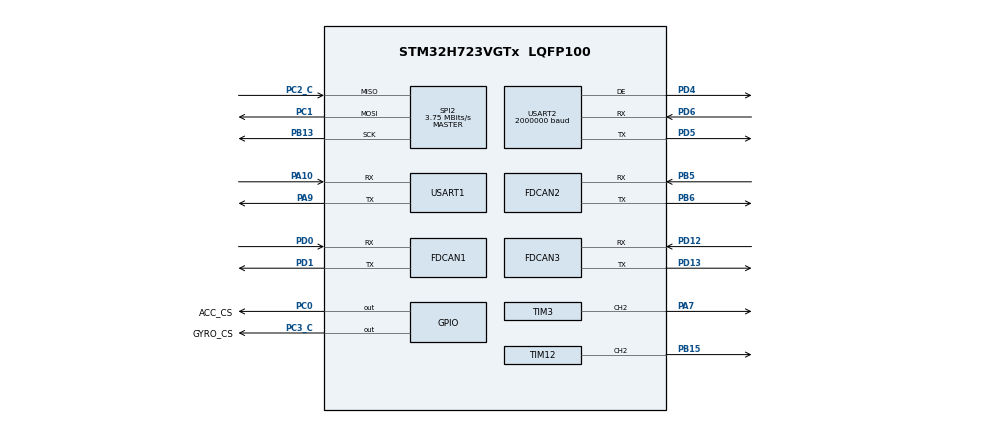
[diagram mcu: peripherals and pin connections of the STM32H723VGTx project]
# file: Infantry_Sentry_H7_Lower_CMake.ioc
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CORTEX_M7.default_mode_Activation=1
Dma.Request0=SPI2_RX
Dma.Request1=SPI2_TX
Dma.Request2=TIM3_CH2
Dma.Request3=USART1_RX
Dma.Request4=USART1_TX
Dma.Request5=USART2_RX
Dma.Request6=USART2_TX
Dma.SPI2_RX.0.Direction=DMA_PERIPH_TO_MEMORY
Dma.SPI2_RX.0.EventEnable=DISABLE
Dma.SPI2_RX.0.FIFOMode=DMA_FIFOMODE_DISABLE
Dma.SPI2_RX.0.Instance=DMA1_Stream0
Dma.SPI2_RX.0.MemDataAlignment=DMA_MDATAALIGN_BYTE
Dma.SPI2_RX.0.MemInc=DMA_MINC_ENABLE
Dma.SPI2_RX.0.Mode=DMA_NORMAL
Dma.SPI2_RX.0.PeriphDataAlignment=DMA_PDATAALIGN_BYTE
Dma.SPI2_RX.0.PeriphInc=DMA_PINC_DISABLE
Dma.SPI2_RX.0.Polarity=HAL_DMAMUX_REQ_GEN_RISING
Dma.SPI2_RX.0.Priority=DMA_PRIORITY_VERY_HIGH
Dma.SPI2_RX.0.RequestNumber=1
Dma.SPI2_RX.0.SignalID=NONE
Dma.SPI2_RX.0.SyncEnable=DISABLE
Dma.SPI2_RX.0.SyncPolarity=HAL_DMAMUX_SYNC_NO_EVENT
Dma.SPI2_RX.0.SyncRequestNumber=1
Dma.SPI2_RX.0.SyncSignalID=NONE
Dma.SPI2_TX.1.Direction=DMA_MEMORY_TO_PERIPH
Dma.SPI2_TX.1.EventEnable=DISABLE
Dma.SPI2_TX.1.FIFOMode=DMA_FIFOMODE_DISABLE
Dma.SPI2_TX.1.Instance=DMA1_Stream1
Dma.SPI2_TX.1.MemDataAlignment=DMA_MDATAALIGN_BYTE
Dma.SPI2_TX.1.MemInc=DMA_MINC_ENABLE
Dma.SPI2_TX.1.Mode=DMA_NORMAL
Dma.SPI2_TX.1.PeriphDataAlignment=DMA_PDATAALIGN_BYTE
Dma.SPI2_TX.1.PeriphInc=DMA_PINC_DISABLE
Dma.SPI2_TX.1.Polarity=HAL_DMAMUX_REQ_GEN_RISING
Dma.SPI2_TX.1.Priority=DMA_PRIORITY_VERY_HIGH
Dma.SPI2_TX.1.RequestNumber=1
Dma.SPI2_TX.1.SignalID=NONE
Dma.SPI2_TX.1.SyncEnable=DISABLE
Dma.SPI2_TX.1.SyncPolarity=HAL_DMAMUX_SYNC_NO_EVENT
Dma.SPI2_TX.1.SyncRequestNumber=1
Dma.SPI2_TX.1.SyncSignalID=NONE
Dma.TIM3_CH2.2.Direction=DMA_MEMORY_TO_PERIPH
Dma.TIM3_CH2.2.EventEnable=DISABLE
Dma.TIM3_CH2.2.FIFOMode=DMA_FIFOMODE_DISABLE
Dma.TIM3_CH2.2.Instance=DMA1_Stream2
Dma.TIM3_CH2.2.MemDataAlignment=DMA_MDATAALIGN_HALFWORD
Dma.TIM3_CH2.2.MemInc=DMA_MINC_ENABLE
Dma.TIM3_CH2.2.Mode=DMA_NORMAL
Dma.TIM3_CH2.2.PeriphDataAlignment=DMA_PDATAALIGN_HALFWORD
Dma.TIM3_CH2.2.PeriphInc=DMA_PINC_DISABLE
Dma.TIM3_CH2.2.Polarity=HAL_DMAMUX_REQ_GEN_RISING
Dma.TIM3_CH2.2.Priority=DMA_PRIORITY_LOW
Dma.TIM3_CH2.2.RequestNumber=1
Dma.TIM3_CH2.2.SignalID=NONE
Dma.TIM3_CH2.2.SyncEnable=DISABLE
Dma.TIM3_CH2.2.SyncPolarity=HAL_DMAMUX_SYNC_NO_EVENT
Dma.TIM3_CH2.2.SyncRequestNumber=1
Dma.TIM3_CH2.2.SyncSignalID=NONE
Dma.USART1_RX.3.Direction=DMA_PERIPH_TO_MEMORY
Dma.USART1_RX.3.EventEnable=DISABLE
Dma.USART1_RX.3.FIFOMode=DMA_FIFOMODE_DISABLE
Dma.USART1_RX.3.Instance=DMA2_Stream0
Dma.USART1_RX.3.MemDataAlignment=DMA_MDATAALIGN_BYTE
Dma.USART1_RX.3.MemInc=DMA_MINC_ENABLE
Dma.USART1_RX.3.Mode=DMA_NORMAL
Dma.USART1_RX.3.PeriphDataAlignment=DMA_PDATAALIGN_BYTE
Dma.USART1_RX.3.PeriphInc=DMA_PINC_DISABLE
Dma.USART1_RX.3.Polarity=HAL_DMAMUX_REQ_GEN_RISING
Dma.USART1_RX.3.Priority=DMA_PRIORITY_LOW
Dma.USART1_RX.3.RequestNumber=1
Dma.USART1_RX.3.SignalID=NONE
Dma.USART1_RX.3.SyncEnable=DISABLE
Dma.USART1_RX.3.SyncPolarity=HAL_DMAMUX_SYNC_NO_EVENT
Dma.USART1_RX.3.SyncRequestNumber=1
Dma.USART1_RX.3.SyncSignalID=NONE
Dma.USART1_TX.4.Direction=DMA_MEMORY_TO_PERIPH
Dma.USART1_TX.4.EventEnable=DISABLE
Dma.USART1_TX.4.FIFOMode=DMA_FIFOMODE_DISABLE
Dma.USART1_TX.4.Instance=DMA2_Stream1
Dma.USART1_TX.4.MemDataAlignment=DMA_MDATAALIGN_BYTE
Dma.USART1_TX.4.MemInc=DMA_MINC_ENABLE
Dma.USART1_TX.4.Mode=DMA_NORMAL
Dma.USART1_TX.4.PeriphDataAlignment=DMA_PDATAALIGN_BYTE
Dma.USART1_TX.4.PeriphInc=DMA_PINC_DISABLE
Dma.USART1_TX.4.Polarity=HAL_DMAMUX_REQ_GEN_RISING
Dma.USART1_TX.4.Priority=DMA_PRIORITY_LOW
Dma.USART1_TX.4.RequestNumber=1
Dma.USART1_TX.4.SignalID=NONE
Dma.USART1_TX.4.SyncEnable=DISABLE
Dma.USART1_TX.4.SyncPolarity=HAL_DMAMUX_SYNC_NO_EVENT
Dma.USART1_TX.4.SyncRequestNumber=1
Dma.USART1_TX.4.SyncSignalID=NONE
Dma.USART2_RX.5.Direction=DMA_PERIPH_TO_MEMORY
Dma.USART2_RX.5.EventEnable=DISABLE
Dma.USART2_RX.5.FIFOMode=DMA_FIFOMODE_DISABLE
Dma.USART2_RX.5.Instance=DMA1_Stream4
Dma.USART2_RX.5.MemDataAlignment=DMA_MDATAALIGN_BYTE
Dma.USART2_RX.5.MemInc=DMA_MINC_ENABLE
Dma.USART2_RX.5.Mode=DMA_NORMAL
Dma.USART2_RX.5.PeriphDataAlignment=DMA_PDATAALIGN_BYTE
Dma.USART2_RX.5.PeriphInc=DMA_PINC_DISABLE
Dma.USART2_RX.5.Polarity=HAL_DMAMUX_REQ_GEN_RISING
Dma.USART2_RX.5.Priority=DMA_PRIORITY_MEDIUM
Dma.USART2_RX.5.RequestNumber=1
Dma.USART2_RX.5.SignalID=NONE
Dma.USART2_RX.5.SyncEnable=DISABLE
Dma.USART2_RX.5.SyncPolarity=HAL_DMAMUX_SYNC_NO_EVENT
Dma.USART2_RX.5.SyncRequestNumber=1
Dma.USART2_RX.5.SyncSignalID=NONE
Dma.USART2_TX.6.Direction=DMA_MEMORY_TO_PERIPH
Dma.USART2_TX.6.EventEnable=DISABLE
Dma.USART2_TX.6.FIFOMode=DMA_FIFOMODE_DISABLE
Dma.USART2_TX.6.Instance=DMA1_Stream5
Dma.USART2_TX.6.MemDataAlignment=DMA_MDATAALIGN_BYTE
Dma.USART2_TX.6.MemInc=DMA_MINC_ENABLE
Dma.USART2_TX.6.Mode=DMA_NORMAL
Dma.USART2_TX.6.PeriphDataAlignment=DMA_PDATAALIGN_BYTE
Dma.USART2_TX.6.PeriphInc=DMA_PINC_DISABLE
Dma.USART2_TX.6.Polarity=HAL_DMAMUX_REQ_GEN_RISING
Dma.USART2_TX.6.Priority=DMA_PRIORITY_MEDIUM
Dma.USART2_TX.6.RequestNumber=1
Dma.USART2_TX.6.SignalID=NONE
Dma.USART2_TX.6.SyncEnable=DISABLE
Dma.USART2_TX.6.SyncPolarity=HAL_DMAMUX_SYNC_NO_EVENT
Dma.USART2_TX.6.SyncRequestNumber=1
Dma.USART2_TX.6.SyncSignalID=NONE
FDCAN1.CalculateBaudRateNominal=1000000
FDCAN1.CalculateTimeBitNominal=1000
FDCAN1.CalculateTimeQuantumNominal=25.0
FDCAN1.DataSyncJumpWidth=2
FDCAN1.DataTimeSeg1=13
FDCAN1.DataTimeSeg2=2
FDCAN1.ExtFiltersNbr=4
FDCAN1.NominalPrescaler=3
FDCAN1.NominalSyncJumpWidth=20
FDCAN1.NominalTimeSeg1=29
FDCAN1.NominalTimeSeg2=10
FDCAN1.RxBuffersNbr=2
FDCAN1.RxFifo0ElmtsNbr=8
FDCAN1.RxFifo1ElmtsNbr=8
FDCAN1.StdFiltersNbr=4
FDCAN1.TxBuffersNbr=8
FDCAN1.TxEventsNbr=8
FDCAN1.TxFifoQueueElmtsNbr=32
FDCAN2.CalculateBaudRateNominal=1000000
FDCAN2.CalculateTimeBitNominal=1000
FDCAN2.CalculateTimeQuantumNominal=25.0
FDCAN2.DataSyncJumpWidth=2
FDCAN2.DataTimeSeg1=13
FDCAN2.ExtFiltersNbr=4
FDCAN2.MessageRAMOffset=0x406
FDCAN2.NominalPrescaler=3
FDCAN2.NominalSyncJumpWidth=20
FDCAN2.NominalTimeSeg1=29
FDCAN2.NominalTimeSeg2=10
FDCAN2.RxBuffersNbr=3
FDCAN2.RxFifo0ElmtsNbr=8
FDCAN2.RxFifo1ElmtsNbr=8
FDCAN2.StdFiltersNbr=4
FDCAN2.TxBuffersNbr=8
FDCAN2.TxEventsNbr=8
FDCAN2.TxFifoQueueElmtsNbr=8
FDCAN3.CalculateBaudRateNominal=1000000
FDCAN3.CalculateTimeBitNominal=1000
FDCAN3.CalculateTimeQuantumNominal=25.0
FDCAN3.DataPrescaler=3
FDCAN3.DataSyncJumpWidth=10
FDCAN3.DataTimeSeg1=29
FDCAN3.DataTimeSeg2=10
FDCAN3.MessageRAMOffset=0x812
FDCAN3.NominalPrescaler=3
FDCAN3.NominalSyncJumpWidth=10
FDCAN3.NominalTimeSeg1=29
FDCAN3.NominalTimeSeg2=10
FDCAN3.RxFifo0ElmtsNbr=4
FDCAN3.StdFiltersNbr=1
FDCAN3.TxFifoQueueElmtsNbr=4
FREERTOS.Tasks01=defaultTask,0,128,StartDefaultTask,Default,NULL,Dynamic,NULL,NULL;IMU_Task,0,512,OS_IMUCallback,As weak,NULL,Dynamic,NULL,NULL;LEDTask,-1,128,OS_LedCallback,As weak,NULL,Dynamic,NULL,NULL;BeepTask,0,256,OS_BeepCallback,As weak,NULL,Dynamic,NULL,NULL;MotorTask,0,512,OS_MotorCallback,As weak,NULL,Dynamic,NULL,NULL;ErrorTask,3,128,OS_ErrorCallback,As weak,NULL,Dynamic,NULL,NULL;RS485_Task,2,512,OS_Board2BoardCallback,As weak,NULL,Dynamic,NULL,NULL;SuperCap,0,256,OS_SuperCapCallback,As weak,NULL,Dynamic,NULL,NULL;JudgeTask,0,256,OS_JudgeCallback,As weak,NULL,Dynamic,NULL,NULL;DetectTask,0,256,OS_DetectCallback,As weak,NULL,Dynamic,NULL,NULL;UI_Task,0,2048,OS_UICallBack,As weak,NULL,Dynamic,NULL,NULL
FREERTOS.configTOTAL_HEAP_SIZE=100000
Mcu.Family=STM32H7
Mcu.Name=STM32H723VGTx
Mcu.Package=LQFP100
NVIC.DMA1_Stream0_IRQn=true\:5\:0\:false\:false\:true\:true\:false\:true\:true
NVIC.DMA1_Stream1_IRQn=true\:5\:0\:false\:false\:true\:true\:false\:true\:true
NVIC.DMA1_Stream2_IRQn=true\:5\:0\:false\:false\:true\:true\:false\:true\:true
NVIC.DMA1_Stream4_IRQn=true\:5\:0\:false\:false\:true\:false\:false\:true\:true
NVIC.DMA1_Stream5_IRQn=true\:5\:0\:false\:false\:true\:false\:false\:true\:true
NVIC.DMA2_Stream0_IRQn=true\:5\:0\:false\:false\:true\:false\:false\:true\:true
NVIC.DMA2_Stream1_IRQn=true\:5\:0\:false\:false\:true\:false\:false\:true\:true
NVIC.FDCAN1_IT0_IRQn=true\:5\:0\:false\:false\:true\:true\:true\:true\:true
NVIC.FDCAN1_IT1_IRQn=true\:5\:0\:false\:false\:true\:true\:true\:true\:true
NVIC.FDCAN2_IT0_IRQn=true\:5\:0\:false\:false\:true\:true\:true\:true\:true
NVIC.FDCAN2_IT1_IRQn=true\:5\:0\:false\:false\:true\:true\:true\:true\:true
NVIC.FDCAN3_IT0_IRQn=true\:5\:0\:false\:false\:true\:true\:true\:true\:true
NVIC.FDCAN3_IT1_IRQn=true\:5\:0\:false\:false\:true\:true\:true\:true\:true
NVIC.PriorityGroup=NVIC_PRIORITYGROUP_4
NVIC.SPI2_IRQn=true\:5\:0\:false\:false\:true\:true\:false\:true\:true
NVIC.TIM2_IRQn=true\:15\:0\:false\:false\:true\:false\:false\:true\:true
NVIC.TIM8_BRK_TIM12_IRQn=true\:5\:0\:false\:false\:true\:true\:true\:true\:true
NVIC.TimeBase=TIM2_IRQn
NVIC.TimeBaseIP=TIM2
NVIC.USART1_IRQn=true\:5\:0\:false\:false\:true\:true\:true\:true\:true
NVIC.USART2_IRQn=true\:5\:0\:false\:false\:true\:true\:true\:true\:true
PA10.Mode=Asynchronous
PA10.Signal=USART1_RX
PA13(JTMS/SWDIO).Mode=Serial_Wire
PA13(JTMS/SWDIO).Signal=DEBUG_JTMS-SWDIO
PA14(JTCK/SWCLK).Mode=Serial_Wire
PA14(JTCK/SWCLK).Signal=DEBUG_JTCK-SWCLK
PA7.GPIO_Speed=GPIO_SPEED_FREQ_VERY_HIGH
PA7.Signal=S_TIM3_CH2
PA9.Mode=Asynchronous
PA9.Signal=USART1_TX
PB13.Mode=Full_Duplex_Master
PB13.Signal=SPI2_SCK
PB15.Signal=S_TIM12_CH2
PB5.Mode=FDCAN_Activate
PB5.Signal=FDCAN2_RX
PB6.Mode=FDCAN_Activate
PB6.Signal=FDCAN2_TX
PC0.GPIO_Label=ACC_CS
PC0.GPIO_Speed=GPIO_SPEED_FREQ_VERY_HIGH
PC0.PinState=GPIO_PIN_SET
PC0.Signal=GPIO_Output
PC1.Mode=Full_Duplex_Master
PC1.Signal=SPI2_MOSI
PC2_C.Mode=Full_Duplex_Master
PC2_C.Signal=SPI2_MISO
PC3_C.GPIO_Label=GYRO_CS
PC3_C.GPIO_Speed=GPIO_SPEED_FREQ_VERY_HIGH
PC3_C.PinState=GPIO_PIN_SET
PC3_C.Signal=GPIO_Output
PD0.Mode=FDCAN_Activate
PD0.Signal=FDCAN1_RX
PD1.Mode=FDCAN_Activate
PD1.Signal=FDCAN1_TX
PD12.Mode=FDCAN_Activate
PD12.Signal=FDCAN3_RX
PD13.Mode=FDCAN_Activate
PD13.Signal=FDCAN3_TX
PD4.Mode=Hardware Flow Control (RS485)
PD4.Signal=USART2_DE
PD5.Mode=Asynchronous
PD5.Signal=USART2_TX
PD6.Mode=Asynchronous
PD6.Signal=USART2_RX
PH0-OSC_IN.Mode=HSE-External-Oscillator
PH0-OSC_IN.Signal=RCC_OSC_IN
PH1-OSC_OUT.Mode=HSE-External-Oscillator
PH1-OSC_OUT.Signal=RCC_OSC_OUT
ProjectManager.HeapSize=0x800
ProjectManager.StackSize=0x1000
ProjectManager.TargetToolchain=CMake
RCC.ADCFreq_Value=48375000
RCC.APB1Freq_Value=120000000
RCC.APB2Freq_Value=120000000
RCC.APB3Freq_Value=120000000
RCC.APB4Freq_Value=120000000
RCC.CortexFreq_Value=480000000
RCC.D1PPRE=RCC_APB3_DIV2
RCC.D2PPRE1=RCC_APB1_DIV2
RCC.D2PPRE2=RCC_APB2_DIV2
RCC.D3PPRE=RCC_APB4_DIV2
RCC.DIVM1=2
RCC.DIVN1=40
RCC.DIVP1=1
RCC.DIVQ1=4
RCC.DIVQ2=3
RCC.HCLKFreq_Value=240000000
RCC.HPRE=RCC_HCLK_DIV2
RCC.HSE_VALUE=24000000
RCC.PLLFRACN=0
RCC.PLLSourceVirtual=RCC_PLLSOURCE_HSE
RCC.SYSCLKFreq_VALUE=480000000
RCC.SYSCLKSource=RCC_SYSCLKSOURCE_PLLCLK
RCC.USBFreq_Value=120000000
SH.S_TIM12_CH2.0=TIM12_CH2,PWM Generation2 CH2
SH.S_TIM3_CH2.0=TIM3_CH2,PWM Generation2 CH2
SPI2.BaudRatePrescaler=SPI_BAUDRATEPRESCALER_32
SPI2.CLKPhase=SPI_PHASE_2EDGE
SPI2.CLKPolarity=SPI_POLARITY_HIGH
SPI2.CalculateBaudRate=3.75 MBits/s
SPI2.DataSize=SPI_DATASIZE_8BIT
SPI2.Direction=SPI_DIRECTION_2LINES
SPI2.Mode=SPI_MODE_MASTER
SPI2.VirtualType=VM_MASTER
TIM12.Channel-PWM\ Generation2\ CH2=TIM_CHANNEL_2
TIM12.Period=1000-1
TIM12.Prescaler=240-1
TIM3.Channel-PWM\ Generation2\ CH2=TIM_CHANNEL_2
TIM3.Period=99
TIM3.Prescaler=2
USART1.VirtualMode-Asynchronous=VM_ASYNC
USART2.BaudRate=2000000
USART2.Parity=PARITY_EVEN
USART2.VirtualMode-Asynchronous=VM_ASYNC
USART2.VirtualMode-Hardware\ Flow\ Control\ (RS485)=VM_ASYNC
USART2.WordLength=WORDLENGTH_9B
VP_FREERTOS_VS_CMSIS_V1.Mode=CMSIS_V1
VP_MEMORYMAP_VS_MEMORYMAP.Mode=CurAppReg
VP_SYS_VS_tim2.Mode=TIM2
VP_TIM3_VS_ClockSourceINT.Mode=Internal
board=custom

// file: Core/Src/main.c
/* USER CODE BEGIN Header */
/**
  ******************************************************************************
  * @file           : main.c
  * @brief          : Main program body
  ******************************************************************************
  * @attention
  *
  * Copyright (c) 2026 STMicroelectronics.
  * All rights reserved.
  *
  * This software is licensed under terms that can be found in the LICENSE file
  * in the root directory of this software component.
  * If no LICENSE file comes with this software, it is provided AS-IS.
  *
  ******************************************************************************
  */
/* USER CODE END Header */
#include "main.h"
#include "cmsis_os.h"
#include "dma.h"
#include "fdcan.h"
#include "spi.h"
#include "tim.h"
#include "usart.h"
#include "gpio.h"

/* USER CODE BEGIN Includes */
#include "bsp_can.h"
#include "beep.h"
#include "USER_B2B.h"
#include "USER_Detcet.h"
#include "bsp_dwt.h"
#include "Judge.h"
/* USER CODE END Includes */

void SystemClock_Config(void);
static void MPU_Config(void);
void MX_FREERTOS_Init(void);

int main(void)
{

  /* MPU Configuration--------------------------------------------------------*/
  MPU_Config();

  /* MCU Configuration--------------------------------------------------------*/

  /* Reset of all peripherals, Initializes the Flash interface and the Systick. */
  HAL_Init();

  /* Configure the system clock */
  SystemClock_Config();

  /* Initialize all configured peripherals */
  MX_GPIO_Init();
  MX_DMA_Init();
  MX_SPI2_Init();
  MX_TIM3_Init();
  MX_FDCAN1_Init();
  MX_FDCAN2_Init();
  MX_FDCAN3_Init();
  MX_USART1_UART_Init();
  MX_USART2_UART_Init();
  MX_TIM12_Init();
  /* USER CODE BEGIN 2 */
  JUDGE_Init();
	CAN_Init();
	Beep_Init();
  DWT_Init(480);
	HAL_Delay(10);
	Detect_InitAll();
  /* USER CODE END 2 */

  /* Call init function for freertos objects (in cmsis_os2.c) */
  MX_FREERTOS_Init();

  /* Start scheduler */
  osKernelStart();

  /* We should never get here as control is now taken by the scheduler */

  /* Infinite loop */
  while (1)
  {

  }
}

void SystemClock_Config(void)
{
  RCC_OscInitTypeDef RCC_OscInitStruct = {0};
  RCC_ClkInitTypeDef RCC_ClkInitStruct = {0};

  /** Supply configuration update enable
  */
  HAL_PWREx_ConfigSupply(PWR_LDO_SUPPLY);

  /** Configure the main internal regulator output voltage
  */
  __HAL_PWR_VOLTAGESCALING_CONFIG(PWR_REGULATOR_VOLTAGE_SCALE0);

  while(!__HAL_PWR_GET_FLAG(PWR_FLAG_VOSRDY)) {}

  /** Initializes the RCC Oscillators according to the specified parameters
  * in the RCC_OscInitTypeDef structure.
  */
  RCC_OscInitStruct.OscillatorType = RCC_OSCILLATORTYPE_HSE;
  RCC_OscInitStruct.HSEState = RCC_HSE_ON;
  RCC_OscInitStruct.PLL.PLLState = RCC_PLL_ON;
  RCC_OscInitStruct.PLL.PLLSource = RCC_PLLSOURCE_HSE;
  RCC_OscInitStruct.PLL.PLLM = 2;
  RCC_OscInitStruct.PLL.PLLN = 40;
  RCC_OscInitStruct.PLL.PLLP = 1;
  RCC_OscInitStruct.PLL.PLLQ = 4;
  RCC_OscInitStruct.PLL.PLLR = 2;
  RCC_OscInitStruct.PLL.PLLRGE = RCC_PLL1VCIRANGE_3;
  RCC_OscInitStruct.PLL.PLLVCOSEL = RCC_PLL1VCOWIDE;
  RCC_OscInitStruct.PLL.PLLFRACN = 0;
  if (HAL_RCC_OscConfig(&RCC_OscInitStruct) != HAL_OK)
  {
    Error_Handler();
  }

  /** Initializes the CPU, AHB and APB buses clocks
  */
  RCC_ClkInitStruct.ClockType = RCC_CLOCKTYPE_HCLK|RCC_CLOCKTYPE_SYSCLK
                              |RCC_CLOCKTYPE_PCLK1|RCC_CLOCKTYPE_PCLK2
                              |RCC_CLOCKTYPE_D3PCLK1|RCC_CLOCKTYPE_D1PCLK1;
  RCC_ClkInitStruct.SYSCLKSource = RCC_SYSCLKSOURCE_PLLCLK;
  RCC_ClkInitStruct.SYSCLKDivider = RCC_SYSCLK_DIV1;
  RCC_ClkInitStruct.AHBCLKDivider = RCC_HCLK_DIV2;
  RCC_ClkInitStruct.APB3CLKDivider = RCC_APB3_DIV2;
  RCC_ClkInitStruct.APB1CLKDivider = RCC_APB1_DIV2;
  RCC_ClkInitStruct.APB2CLKDivider = RCC_APB2_DIV2;
  RCC_ClkInitStruct.APB4CLKDivider = RCC_APB4_DIV2;

  if (HAL_RCC_ClockConfig(&RCC_ClkInitStruct, FLASH_LATENCY_3) != HAL_OK)
  {
    Error_Handler();
  }
}

 /* MPU Configuration */

void MPU_Config(void)
{
  MPU_Region_InitTypeDef MPU_InitStruct = {0};

  /* Disables the MPU */
  HAL_MPU_Disable();

  /** Initializes and configures the Region and the memory to be protected
  */
  MPU_InitStruct.Enable = MPU_REGION_ENABLE;
  MPU_InitStruct.Number = MPU_REGION_NUMBER0;
  MPU_InitStruct.BaseAddress = 0x0;
  MPU_InitStruct.Size = MPU_REGION_SIZE_4GB;
  MPU_InitStruct.SubRegionDisable = 0x87;
  MPU_InitStruct.TypeExtField = MPU_TEX_LEVEL0;
  MPU_InitStruct.AccessPermission = MPU_REGION_NO_ACCESS;
  MPU_InitStruct.DisableExec = MPU_INSTRUCTION_ACCESS_DISABLE;
  MPU_InitStruct.IsShareable = MPU_ACCESS_SHAREABLE;
  MPU_InitStruct.IsCacheable = MPU_ACCESS_NOT_CACHEABLE;
  MPU_InitStruct.IsBufferable = MPU_ACCESS_NOT_BUFFERABLE;

  HAL_MPU_ConfigRegion(&MPU_InitStruct);
  /* Enables the MPU */
  HAL_MPU_Enable(MPU_PRIVILEGED_DEFAULT);

}

void HAL_TIM_PeriodElapsedCallback(TIM_HandleTypeDef *htim)
{
  if (htim->Instance == TIM2)
  {
    HAL_IncTick();
  }
}

void Error_Handler(void)
{
  __disable_irq();
  while (1)
  {
  }
}

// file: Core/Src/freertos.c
/* USER CODE BEGIN Header */
/**
  ******************************************************************************
  * File Name          : freertos.c
  * Description        : Code for freertos applications
  ******************************************************************************
  * @attention
  *
  * Copyright (c) 2026 STMicroelectronics.
  * All rights reserved.
  *
  * This software is licensed under terms that can be found in the LICENSE file
  * in the root directory of this software component.
  * If no LICENSE file comes with this software, it is provided AS-IS.
  *
  ******************************************************************************
  */
/* USER CODE END Header */

#include "FreeRTOS.h"
#include "task.h"
#include "main.h"
#include "cmsis_os.h"

osThreadId defaultTaskHandle;
osThreadId IMU_TaskHandle;
osThreadId LEDTaskHandle;
osThreadId BeepTaskHandle;
osThreadId MotorTaskHandle;
osThreadId ErrorTaskHandle;
osThreadId RS485_TaskHandle;
osThreadId SuperCapHandle;
osThreadId JudgeTaskHandle;
osThreadId DetectTaskHandle;
osThreadId UI_TaskHandle;

void StartDefaultTask(void const * argument);
void OS_IMUCallback(void const * argument);
void OS_LedCallback(void const * argument);
void OS_BeepCallback(void const * argument);
void OS_MotorCallback(void const * argument);
void OS_ErrorCallback(void const * argument);
void OS_Board2BoardCallback(void const * argument);
void OS_SuperCapCallback(void const * argument);
void OS_JudgeCallback(void const * argument);
void OS_DetectCallback(void const * argument);
void OS_UICallBack(void const * argument);

void MX_FREERTOS_Init(void); /* (MISRA C 2004 rule 8.1) */

/* GetIdleTaskMemory prototype (linked to static allocation support) */
void vApplicationGetIdleTaskMemory( StaticTask_t **ppxIdleTaskTCBBuffer, StackType_t **ppxIdleTaskStackBuffer, uint32_t *pulIdleTaskStackSize );

/* USER CODE BEGIN GET_IDLE_TASK_MEMORY */
static StaticTask_t xIdleTaskTCBBuffer;
static StackType_t xIdleStack[configMINIMAL_STACK_SIZE];

void vApplicationGetIdleTaskMemory( StaticTask_t **ppxIdleTaskTCBBuffer, StackType_t **ppxIdleTaskStackBuffer, uint32_t *pulIdleTaskStackSize )
{
  *ppxIdleTaskTCBBuffer = &xIdleTaskTCBBuffer;
  *ppxIdleTaskStackBuffer = &xIdleStack[0];
  *pulIdleTaskStackSize = configMINIMAL_STACK_SIZE;
  /* place for user code */
}
/* USER CODE END GET_IDLE_TASK_MEMORY */

void MX_FREERTOS_Init(void) {

  /* Create the thread(s) */
  /* definition and creation of defaultTask */
  osThreadDef(defaultTask, StartDefaultTask, osPriorityNormal, 0, 128);
  defaultTaskHandle = osThreadCreate(osThread(defaultTask), NULL);

  /* definition and creation of IMU_Task */
  osThreadDef(IMU_Task, OS_IMUCallback, osPriorityNormal, 0, 512);
  IMU_TaskHandle = osThreadCreate(osThread(IMU_Task), NULL);

  /* definition and creation of LEDTask */
  osThreadDef(LEDTask, OS_LedCallback, osPriorityBelowNormal, 0, 128);
  LEDTaskHandle = osThreadCreate(osThread(LEDTask), NULL);

  /* definition and creation of BeepTask */
  osThreadDef(BeepTask, OS_BeepCallback, osPriorityNormal, 0, 256);
  BeepTaskHandle = osThreadCreate(osThread(BeepTask), NULL);

  /* definition and creation of MotorTask */
  osThreadDef(MotorTask, OS_MotorCallback, osPriorityNormal, 0, 512);
  MotorTaskHandle = osThreadCreate(osThread(MotorTask), NULL);

  /* definition and creation of ErrorTask */
  osThreadDef(ErrorTask, OS_ErrorCallback, osPriorityRealtime, 0, 128);
  ErrorTaskHandle = osThreadCreate(osThread(ErrorTask), NULL);

  /* definition and creation of RS485_Task */
  osThreadDef(RS485_Task, OS_Board2BoardCallback, osPriorityHigh, 0, 512);
  RS485_TaskHandle = osThreadCreate(osThread(RS485_Task), NULL);

  /* definition and creation of SuperCap */
  osThreadDef(SuperCap, OS_SuperCapCallback, osPriorityNormal, 0, 256);
  SuperCapHandle = osThreadCreate(osThread(SuperCap), NULL);

  /* definition and creation of JudgeTask */
  osThreadDef(JudgeTask, OS_JudgeCallback, osPriorityNormal, 0, 256);
  JudgeTaskHandle = osThreadCreate(osThread(JudgeTask), NULL);

  /* definition and creation of DetectTask */
  osThreadDef(DetectTask, OS_DetectCallback, osPriorityNormal, 0, 256);
  DetectTaskHandle = osThreadCreate(osThread(DetectTask), NULL);

  /* definition and creation of UI_Task */
  osThreadDef(UI_Task, OS_UICallBack, osPriorityNormal, 0, 2048);
  UI_TaskHandle = osThreadCreate(osThread(UI_Task), NULL);

}

void StartDefaultTask(void const * argument)
{
  for(;;)
  {
    osDelay(1);
  }
}

__weak void OS_IMUCallback(void const * argument)
{
  for(;;)
  {
    osDelay(1);
  }
}

__weak void OS_LedCallback(void const * argument)
{
  for(;;)
  {
    osDelay(1);
  }
}

__weak void OS_BeepCallback(void const * argument)
{
  for(;;)
  {
    osDelay(1);
  }
}

__weak void OS_MotorCallback(void const * argument)
{
  for(;;)
  {
    osDelay(1);
  }
}

__weak void OS_ErrorCallback(void const * argument)
{
  for(;;)
  {
    osDelay(1);
  }
}

__weak void OS_Board2BoardCallback(void const * argument)
{
  for(;;)
  {
    osDelay(1);
  }
}

__weak void OS_SuperCapCallback(void const * argument)
{
  for(;;)
  {
    osDelay(1);
  }
}

__weak void OS_JudgeCallback(void const * argument)
{
  for(;;)
  {
    osDelay(1);
  }
}

__weak void OS_DetectCallback(void const * argument)
{
  for(;;)
  {
    osDelay(1);
  }
}

__weak void OS_UICallBack(void const * argument)
{
  for(;;)
  {
    osDelay(1);
  }
}
